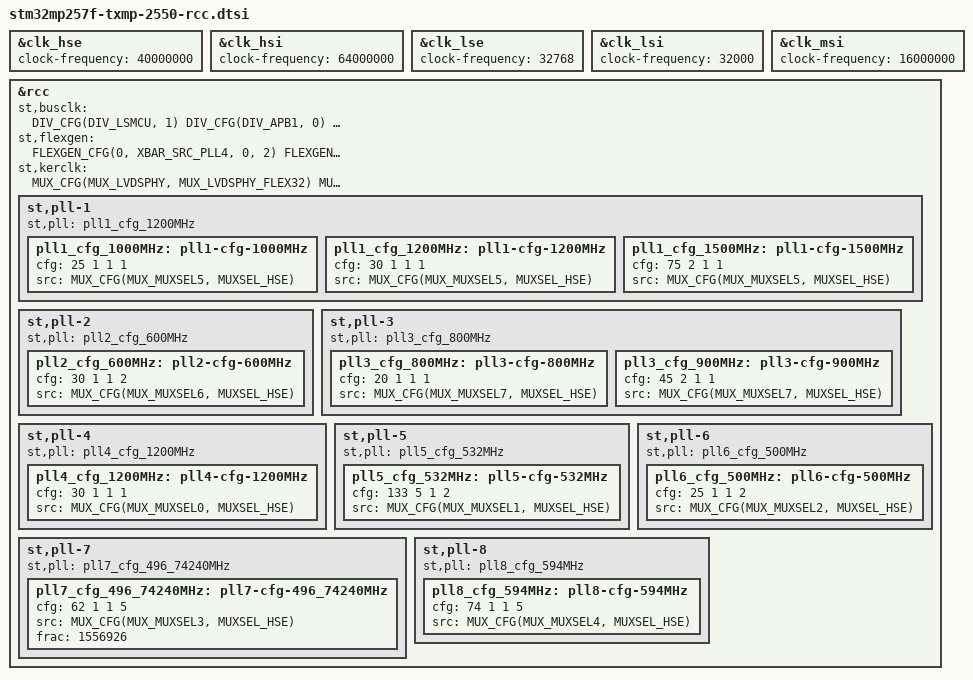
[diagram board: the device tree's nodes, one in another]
// SPDX-License-Identifier: (GPL-2.0-or-later OR BSD-3-Clause)
/*
 * Copyright (C) 2024, STMicroelectronics - All Rights Reserved
 * Author: STM32CubeMX code generation for STMicroelectronics.
 */

/* For more information on Device Tree configuration, please refer to
 * https://wiki.st.com/stm32mpu/wiki/Category:Device_tree_configuration
 */

#include <dt-bindings/clock/stm32mp25-clksrc.h>

&clk_hse {
	clock-frequency = <40000000>;
};

&clk_hsi {
	clock-frequency = <64000000>;
};

&clk_lse {
	clock-frequency = <32768>;
};

&clk_lsi {
	clock-frequency = <32000>;
};

&clk_msi {
	clock-frequency = <16000000>;
};

&rcc {
	st,busclk = <
		DIV_CFG(DIV_LSMCU, 1)
		DIV_CFG(DIV_APB1, 0)
		DIV_CFG(DIV_APB2, 0)
		DIV_CFG(DIV_APB3, 0)
		DIV_CFG(DIV_APB4, 0)
		DIV_CFG(DIV_APBDBG, 0)
	>;
	st,flexgen = <
		FLEXGEN_CFG(0, XBAR_SRC_PLL4, 0, 2) /* HS_MCU, LS_MCU */
		FLEXGEN_CFG(1, XBAR_SRC_PLL4, 0, 5) /* ICN_SDMMC */
		FLEXGEN_CFG(2, XBAR_SRC_PLL4, 0, 1) /* ICN_DDR */
		FLEXGEN_CFG(3, XBAR_SRC_PLL4, 0, 2) /* ICN_DISPLAY */
		FLEXGEN_CFG(4, XBAR_SRC_PLL4, 0, 3) /* PCIE, USB3DR, USB2[EO]HCI, ETH[12] */
		FLEXGEN_CFG(5, XBAR_SRC_PLL4, 0, 2) /* BOOTROM, GIC400 */
		FLEXGEN_CFG(6, XBAR_SRC_PLL4, 0, 1) /* VDEC, VENC, VID */
		FLEXGEN_CFG(7, XBAR_SRC_PLL4, 0, 11) /* LPTIM[12] */
//		FLEXGEN_CFG(8, XBAR_SRC_HSI_KER, 0, 0) /* USART2, UART4 */
//		FLEXGEN_CFG(9, XBAR_SRC_HSI_KER, 0, 0) /* USART3, UART5 */
		FLEXGEN_CFG(10, XBAR_SRC_PLL4, 0, 9) /* SPI[23] */
//		FLEXGEN_CFG(11, XBAR_SRC_PLL?, 0, ?) /* SPDIFRX */
//		FLEXGEN_CFG(12, XBAR_SRC_PLL?, 0, ?) /* I2C[12], I3C[12] */
//		FLEXGEN_CFG(13, XBAR_SRC_PLL?, 0, ?) /* I2C[35], I3C3 */
//		FLEXGEN_CFG(14, XBAR_SRC_PLL?, 0, ?) /* I2C[46] */
		FLEXGEN_CFG(15, XBAR_SRC_PLL4, 0, 9) /* I2C7 */
		FLEXGEN_CFG(16, XBAR_SRC_PLL4, 0, 5) /* SPI1 */
		FLEXGEN_CFG(17, XBAR_SRC_PLL4, 0, 9) /* SPI[45] */
		FLEXGEN_CFG(18, XBAR_SRC_PLL4, 0, 9) /* SPI[67] */
//		FLEXGEN_CFG(19, XBAR_SRC_HSI_KER, 0, 0) /* USART1 */
//		FLEXGEN_CFG(20, XBAR_SRC_HSI_KER, 0, 0) /* USART6 */
//		FLEXGEN_CFG(21, XBAR_SRC_HSI_KER, 0, 0) /* UART[78] */
//		FLEXGEN_CFG(22, XBAR_SRC_HSI_KER, 0, 0) /* UART9 */
		FLEXGEN_CFG(23, XBAR_SRC_PLL7, 0, 10) /* SAI1, MDF1 */
//		FLEXGEN_CFG(24, XBAR_SRC_PLL7, 0, 10) /* SAI2 */
//		FLEXGEN_CFG(25, XBAR_SRC_PLL7, 0, 10) /* SAI[34] */
		FLEXGEN_CFG(26, XBAR_SRC_PLL5, 0, 3) /* FDCAN */
		FLEXGEN_CFG(27, XBAR_SRC_PLL8, 0, 1) /* LTDC (DSI pix or DSI IO) */
		FLEXGEN_CFG(28, XBAR_SRC_PLL8, 0, 21) /* DSIPHY */
		FLEXGEN_CFG(29, XBAR_SRC_PLL5, 0, 1) /* CSI, DCMIPP */
		FLEXGEN_CFG(30, XBAR_SRC_HSE_KER, 0, 1) /* CSITXESC */
		FLEXGEN_CFG(31, XBAR_SRC_PLL5, 0, 19) /* CSIPHY */
		FLEXGEN_CFG(32, XBAR_SRC_PLL5, 0, 19) /* LVDSPHY */
		FLEXGEN_CFG(33, XBAR_SRC_PLL4, 0, 23) /* STGEN */
		FLEXGEN_CFG(34, XBAR_SRC_PLL4, 0, 47) /* USB3PCIEPHY */
//		FLEXGEN_CFG(35, XBAR_SRC_PLL?, 0, ?) /* USBTC */
//		FLEXGEN_CFG(36, XBAR_SRC_PLL?, 0, ?) /* I3C4 */
		FLEXGEN_CFG(37, XBAR_SRC_PLL4, 0, 9) /* SPI8 */
//		FLEXGEN_CFG(38, XBAR_SRC_PLL?, 0, ?) /* I2C8 */
//		FLEXGEN_CFG(39, XBAR_SRC_PLL?, 0, ?) /* LPUART1 */
//		FLEXGEN_CFG(40, XBAR_SRC_PLL?, 0, ?) /* LPTIM3 */
//		FLEXGEN_CFG(41, XBAR_SRC_PLL?, 0, ?) /* LPTIM[45] */
//		FLEXGEN_CFG(42, XBAR_SRC_PLL?, 0, ?) /* ADF1 */
		FLEXGEN_CFG(43, XBAR_SRC_PLL4, 0, 23) /* TSDBG */
		FLEXGEN_CFG(44, XBAR_SRC_PLL4, 0, 5) /* TPIU */
		FLEXGEN_CFG(45, XBAR_SRC_PLL4, 0, 2) /* ATB, ETR */
//		FLEXGEN_CFG(46, XBAR_SRC_PLL?, 0, ?) /* ADC12 */
//		FLEXGEN_CFG(47, XBAR_SRC_PLL?, 0, ?) /* ADC3 */
//		FLEXGEN_CFG(48, XBAR_SRC_PLL?, 0, ?) /* OSPI1 */
//		FLEXGEN_CFG(49, XBAR_SRC_PLL?, 0, ?) /* OSPI2 */
//		FLEXGEN_CFG(50, XBAR_SRC_PLL?, 0, ?) /* FMC */
		FLEXGEN_CFG(51, XBAR_SRC_PLL4, 0, 5) /* SDMMC1 */
		FLEXGEN_CFG(52, XBAR_SRC_PLL4, 0, 5) /* SDMMC2 */
		FLEXGEN_CFG(53, XBAR_SRC_PLL4, 0, 5) /* SDMMC3 */
		FLEXGEN_CFG(54, XBAR_SRC_PLL6, 0, 9) /* ETH1, ETHSW */
		FLEXGEN_CFG(55, XBAR_SRC_PLL6, 0, 9) /* ETH2 */
		FLEXGEN_CFG(56, XBAR_SRC_PLL4, 0, 5) /* ETH1PTP, ETH2PTP */
		FLEXGEN_CFG(57, XBAR_SRC_HSE_KER, 0, 1) /* USB2PHY1 */
		FLEXGEN_CFG(58, XBAR_SRC_HSE_KER, 0, 1) /* USB2PHY2 */
		FLEXGEN_CFG(59, XBAR_SRC_PLL4, 0, 1) /* GPU */
		FLEXGEN_CFG(60, XBAR_SRC_PLL4, 0, 23) /* ETHSWREF */
//		FLEXGEN_CFG(61, XBAR_SRC_PLL?, 0, ?) /* MCO1 */
//		FLEXGEN_CFG(62, XBAR_SRC_PLL?, 0, ?) /* MCO2 */
		FLEXGEN_CFG(63, XBAR_SRC_PLL4, 0, 2) /* CPU1_EXT2F */
	>;
	st,kerclk = <
		MUX_CFG(MUX_LVDSPHY, MUX_LVDSPHY_FLEX32)
		MUX_CFG(MUX_D3PER, MUX_D3PER_LSI)
		MUX_CFG(MUX_USB2PHY1, MUX_USB2PHY1_FLEX57)
		MUX_CFG(MUX_USB2PHY2, MUX_USB2PHY2_FLEX58)
		MUX_CFG(MUX_USB3PCIEPHY, MUX_USB3PCIEPHY_FLEX34)
		MUX_CFG(MUX_DSIBLANE, MUX_DSIBLANE_DSIPHY)
		MUX_CFG(MUX_DSIPHY, MUX_DSIPHY_FLEX28)
		MUX_CFG(MUX_RTC, MUX_RTC_LSE)
	>;

	st,pll-1 {
		st,pll = <&pll1_cfg_1200MHz>;

		pll1_cfg_1000MHz: pll1-cfg-1000MHz {
			cfg = <25 1 1 1>;
			src = <MUX_CFG(MUX_MUXSEL5, MUXSEL_HSE)>;
		};

		pll1_cfg_1200MHz: pll1-cfg-1200MHz {
			cfg = <30 1 1 1>;
			src = <MUX_CFG(MUX_MUXSEL5, MUXSEL_HSE)>;
		};

		pll1_cfg_1500MHz: pll1-cfg-1500MHz {
			cfg = <75 2 1 1>;
			src = <MUX_CFG(MUX_MUXSEL5, MUXSEL_HSE)>;
		};
	};

	st,pll-2 {
		st,pll = <&pll2_cfg_600MHz>;

		pll2_cfg_600MHz: pll2-cfg-600MHz {
			cfg = <30 1 1 2>;
			src = <MUX_CFG(MUX_MUXSEL6, MUXSEL_HSE)>;
		};
	};

	st,pll-3 {
		st,pll = <&pll3_cfg_800MHz>;

		pll3_cfg_800MHz: pll3-cfg-800MHz {
			cfg = <20 1 1 1>;
			src = <MUX_CFG(MUX_MUXSEL7, MUXSEL_HSE)>;
		};

		pll3_cfg_900MHz: pll3-cfg-900MHz {
			cfg = <45 2 1 1>;
			src = <MUX_CFG(MUX_MUXSEL7, MUXSEL_HSE)>;
		};
	};

	st,pll-4 {
		st,pll = <&pll4_cfg_1200MHz>;

		pll4_cfg_1200MHz: pll4-cfg-1200MHz {
			cfg = <30 1 1 1>;
			src = <MUX_CFG(MUX_MUXSEL0, MUXSEL_HSE)>;
		};
	};

	st,pll-5 {
		st,pll = <&pll5_cfg_532MHz>;

		pll5_cfg_532MHz: pll5-cfg-532MHz {
			cfg = <133 5 1 2>;
			src = <MUX_CFG(MUX_MUXSEL1, MUXSEL_HSE)>;
		};
	};

	st,pll-6 {
		st,pll = <&pll6_cfg_500MHz>;

		pll6_cfg_500MHz: pll6-cfg-500MHz {
			cfg = <25 1 1 2>;
			src = <MUX_CFG(MUX_MUXSEL2, MUXSEL_HSE)>;
		};
	};

	st,pll-7 {
		/* calculated to create a 45.1584 MHz base clock for audio */
		st,pll = <&pll7_cfg_496_74240MHz>;

		pll7_cfg_496_74240MHz: pll7-cfg-496_74240MHz {
			cfg = <62 1 1 5>;
			src = <MUX_CFG(MUX_MUXSEL3, MUXSEL_HSE)>;
			frac = <1556926>;
		};
	};

	st,pll-8 {
		st,pll = <&pll8_cfg_594MHz>;

		pll8_cfg_594MHz: pll8-cfg-594MHz {
			cfg = <74 1 1 5>;
			src = <MUX_CFG(MUX_MUXSEL4, MUXSEL_HSE)>;
		};
	};
};
